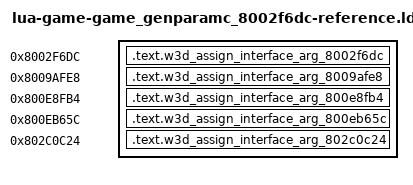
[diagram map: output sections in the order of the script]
/* Generated reference-only placements. All bodies are source-built. */
OUTPUT_FORMAT("elf32-powerpc")
OUTPUT_ARCH(powerpc)
ENTRY(w3d_assign_interface_arg_8002f6dc)
_SDA_BASE_ = 0x804b2540;
_SDA2_BASE_ = 0x804c2540;
SECTIONS {
  .text.w3d_assign_interface_arg_8002f6dc 0x8002f6dc : { *(.text.w3d_assign_interface_arg_8002f6dc) }
  .text.w3d_assign_interface_arg_8009afe8 0x8009afe8 : { *(.text.w3d_assign_interface_arg_8009afe8) }
  .text.w3d_assign_interface_arg_800e8fb4 0x800e8fb4 : { *(.text.w3d_assign_interface_arg_800e8fb4) }
  .text.w3d_assign_interface_arg_800eb65c 0x800eb65c : { *(.text.w3d_assign_interface_arg_800eb65c) }
  .text.w3d_assign_interface_arg_802c0c24 0x802c0c24 : { *(.text.w3d_assign_interface_arg_802c0c24) }
  /DISCARD/ : { *(.text*) *(.rodata*) *(.data*) *(.bss*) *(.sdata*) *(.sbss*) *(.comment) }
}
